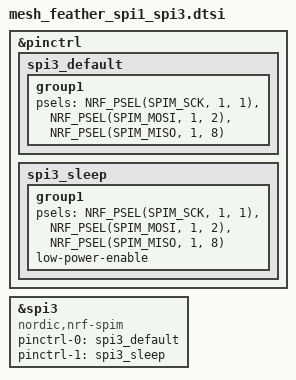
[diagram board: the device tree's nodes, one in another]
/*
 * Copyright (c) 2018 Peter Bigot Consulting, LLC
 *
 * SPDX-License-Identifier: Apache-2.0
 */

/* Add SPI1 support on Particle Mesh via nRF52840 SPI3
 *
 * NOTE: This file is replicated in particle_{argon,boron,xenon}.
 * Changes should be made in all instances.
 */

&pinctrl {
	spi3_default: spi3_default {
		group1 {
			psels = <NRF_PSEL(SPIM_SCK, 1, 1)>,
				<NRF_PSEL(SPIM_MOSI, 1, 2)>,
				<NRF_PSEL(SPIM_MISO, 1, 8)>;
		};
	};

	spi3_sleep: spi3_sleep {
		group1 {
			psels = <NRF_PSEL(SPIM_SCK, 1, 1)>,
				<NRF_PSEL(SPIM_MOSI, 1, 2)>,
				<NRF_PSEL(SPIM_MISO, 1, 8)>;
			low-power-enable;
		};
	};
};

&spi3 { /* feather SPI */
	compatible = "nordic,nrf-spim";
	status = "okay";
	pinctrl-0 = <&spi3_default>;
	pinctrl-1 = <&spi3_sleep>;
	pinctrl-names = "default", "sleep";
};

